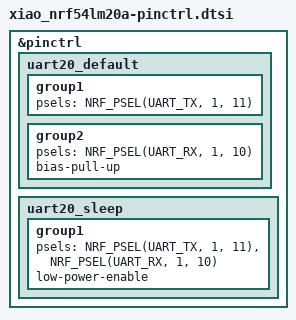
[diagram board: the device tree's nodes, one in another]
/*
 * Copyright (c) 2026
 * SPDX-License-Identifier: Apache-2.0
 */

&pinctrl {
	/omit-if-no-ref/ uart20_default: uart20_default {
		group1 {
			/* P1.11 is connected to the on-board SAMD11 RX input. */
			psels = <NRF_PSEL(UART_TX, 1, 11)>;
		};

		group2 {
			/* P1.10 is connected to the on-board SAMD11 TX output. */
			psels = <NRF_PSEL(UART_RX, 1, 10)>;
			bias-pull-up;
		};
	};

	/omit-if-no-ref/ uart20_sleep: uart20_sleep {
		group1 {
			psels = <NRF_PSEL(UART_TX, 1, 11)>,
				<NRF_PSEL(UART_RX, 1, 10)>;
			low-power-enable;
		};
	};
};
